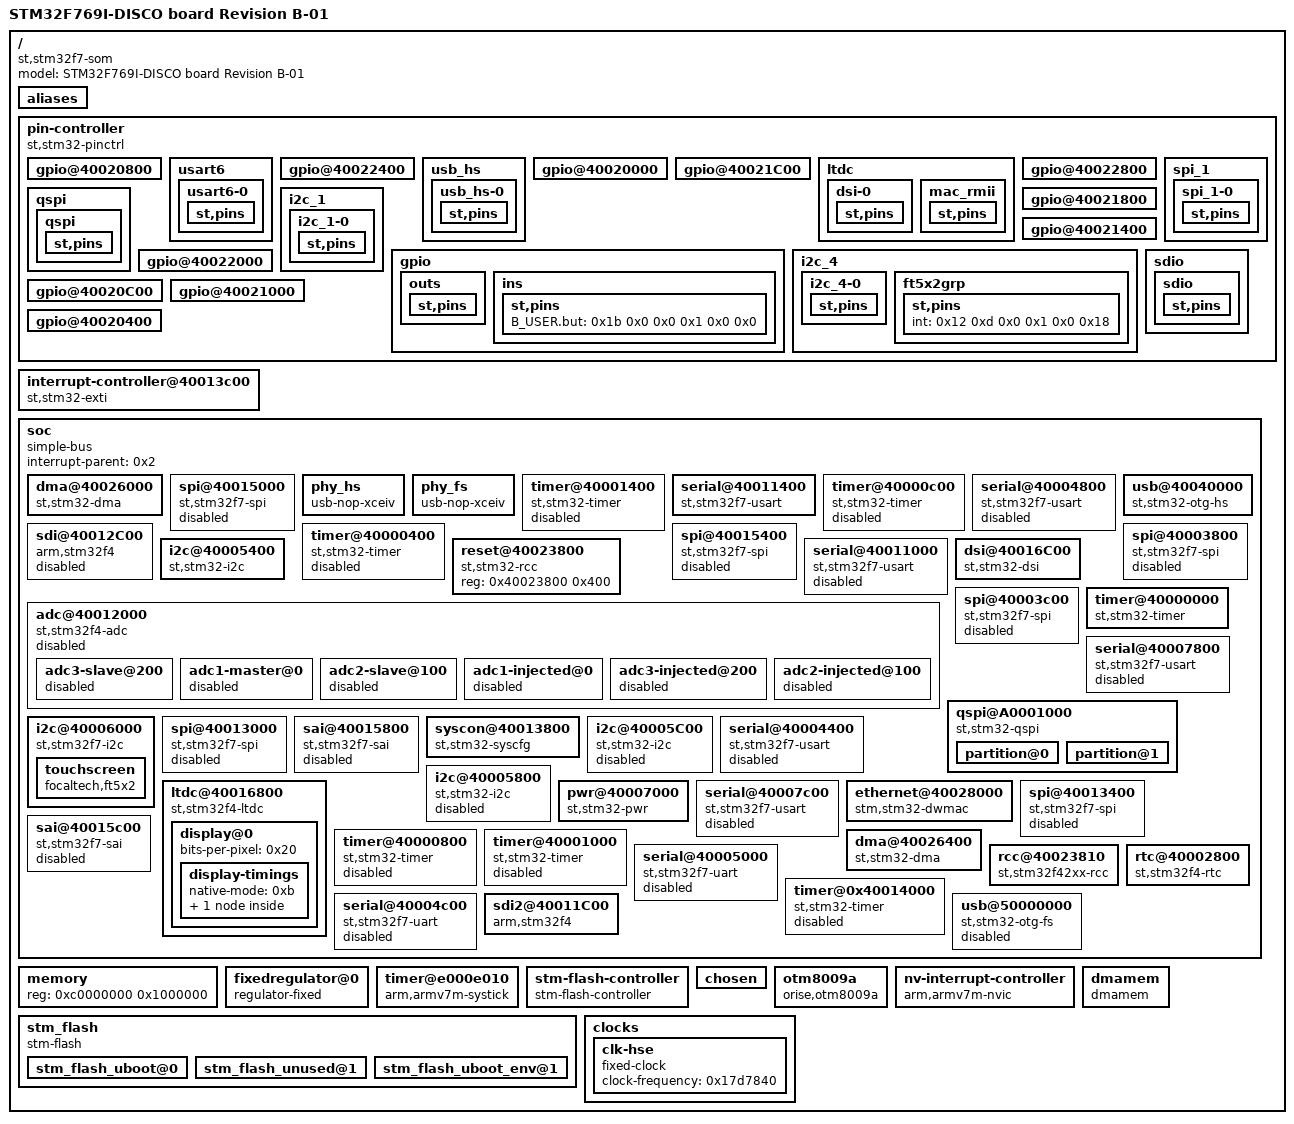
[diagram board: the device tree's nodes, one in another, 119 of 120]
/dts-v1/;

/ {
	model = "STM32F769I-DISCO board Revision B-01";
	#size-cells = <0x1>;
	#address-cells = <0x1>;
	compatible = "st,stm32f7-som", "st,stm32f7";

	aliases {
		spi3 = "/soc/spi@40013400";
		i2c2 = "/soc/i2c@40005C00";
		i2c1 = "/soc/i2c@40005800";
		gpio8 = "/pin-controller/gpio@40022000";
		ethernet0 = "/soc/ethernet@40028000";
		gpio2 = "/pin-controller/gpio@40020800";
		gpio0 = "/pin-controller/gpio@40020000";
		serial4 = "/soc/serial@40005000";
		serial7 = "/soc/serial@40007c00";
		spi5 = "/soc/spi@40015400";
		serial6 = "/soc/serial@40007800";
		serial3 = "/soc/serial@40004c00";
		gpio6 = "/pin-controller/gpio@40021800";
		i2c0 = "/soc/i2c@40005400";
		serial2 = "/soc/serial@40004800";
		serial0 = "/soc/serial@40011000";
		serial5 = "/soc/serial@40011400";
		gpio4 = "/pin-controller/gpio@40021000";
		gpio9 = "/pin-controller/gpio@40022400";
		spi1 = "/soc/spi@40003800";
		gpio10 = "/pin-controller/gpio@40022800";
		spi4 = "/soc/spi@40015000";
		gpio7 = "/pin-controller/gpio@40021C00";
		gpio1 = "/pin-controller/gpio@40020400";
		spi2 = "/soc/spi@40003c00";
		gpio5 = "/pin-controller/gpio@40021400";
		gpio3 = "/pin-controller/gpio@40020C00";
		spi0 = "/soc/spi@40013000";
		serial1 = "/soc/serial@40004400";
		i2c3 = "/soc/i2c@40006000";
	};

	pin-controller {
		#size-cells = <0x1>;
		ranges = <0x0 0x40020000 0x3000>;
		interrupt-parent = <0x3>;
		#address-cells = <0x1>;
		compatible = "st,stm32-pinctrl";
		st,syscfg = <0x19 0x8>;

		gpio@40020800 {
			resets = <0x4 0x82>;
			st,bank-name = "GPIOC";
			#gpio-cells = <0x2>;
			phandle = <0x1a>;
			gpio-controller;
			linux,phandle = <0x1a>;
			reg = <0x800 0x400>;
			clocks = <0x1 0x0 0x2>;
		};

		usart6 {

			usart6-0 {
				phandle = <0x8>;
				linux,phandle = <0x8>;

				st,pins {
					tx = <0x1a 0x6 0x22 0x0 0x0 0x0>;
					rx = <0x1a 0x7 0x22 0x0 0x0 0x0>;
				};
			};
		};

		gpio@40022400 {
			resets = <0x4 0x89>;
			st,bank-name = "GPIOJ";
			#gpio-cells = <0x2>;
			phandle = <0x13>;
			gpio-controller;
			linux,phandle = <0x13>;
			reg = <0x2400 0x400>;
			clocks = <0x1 0x0 0x9>;
		};

		usb_hs {

			usb_hs-0 {
				phandle = <0xe>;
				linux,phandle = <0xe>;

				st,pins {
					clk = <0x1b 0x5 0x2a 0x0 0x0 0x18>;
					data7 = <0x1e 0x5 0x2a 0x0 0x0 0x18>;
					dir = <0x12 0xb 0x2a 0x0 0x0 0x18>;
					data5 = <0x1e 0xc 0x2a 0x0 0x0 0x18>;
					data6 = <0x1e 0xd 0x2a 0x0 0x0 0x18>;
					data3 = <0x1e 0xa 0x2a 0x0 0x0 0x18>;
					nxt = <0x20 0x4 0x2a 0x0 0x0 0x18>;
					data2 = <0x1e 0x1 0x2a 0x0 0x0 0x18>;
					data1 = <0x1e 0x0 0x2a 0x0 0x0 0x18>;
					data4 = <0x1e 0xb 0x2a 0x0 0x0 0x18>;
					stp = <0x1a 0x0 0x2a 0x0 0x0 0x18>;
					data0 = <0x1b 0x3 0x2a 0x0 0x0 0x18>;
				};
			};
		};

		gpio@40020000 {
			resets = <0x4 0x80>;
			st,bank-name = "GPIOA";
			#gpio-cells = <0x2>;
			phandle = <0x1b>;
			gpio-controller;
			linux,phandle = <0x1b>;
			reg = <0x0 0x400>;
			clocks = <0x1 0x0 0x0>;
		};

		gpio@40021C00 {
			resets = <0x4 0x87>;
			st,bank-name = "GPIOH";
			#gpio-cells = <0x2>;
			phandle = <0x20>;
			gpio-controller;
			linux,phandle = <0x20>;
			reg = <0x1c00 0x400>;
			clocks = <0x1 0x0 0x7>;
		};

		ltdc {

			dsi-0 {
				phandle = <0x14>;
				linux,phandle = <0x14>;

				st,pins {
					bl = <0x12 0xe 0x1 0x1 0x0 0x0>;
					te = <0x13 0x2 0x36 0x0 0x0 0x18>;
				};
			};

			mac_rmii {
				phandle = <0xd>;
				linux,phandle = <0xd>;

				st,pins {
					txd1 = <0x1c 0xe 0x2e 0x0 0x0 0x18>;
					tx_en = <0x1c 0xb 0x2e 0x0 0x0 0x18>;
					mdio = <0x1b 0x2 0x2e 0x0 0x0 0x18>;
					crs_dv = <0x1b 0x7 0x2e 0x0 0x0 0x18>;
					ref_clk = <0x1b 0x1 0x2e 0x0 0x0 0x18>;
					mdc = <0x1a 0x1 0x2e 0x0 0x0 0x18>;
					rxd1 = <0x1a 0x5 0x2e 0x0 0x0 0x18>;
					txd0 = <0x1c 0xd 0x2e 0x0 0x0 0x18>;
					rxd0 = <0x1a 0x4 0x2e 0x0 0x0 0x18>;
					rx_er = <0x1d 0x5 0x2e 0x0 0x0 0x18>;
				};
			};
		};

		gpio@40022800 {
			resets = <0x4 0x8a>;
			st,bank-name = "GPIOK";
			#gpio-cells = <0x2>;
			gpio-controller;
			reg = <0x2800 0x400>;
			clocks = <0x1 0x0 0xa>;
		};

		spi_1 {

			spi_1-0 {

				st,pins {
					clk = <0x1e 0x2 0x26 0x1 0x0 0x10>;
					d3 = <0x1d 0xd 0x26 0x1 0x0 0x10>;
					d1 = <0x1a 0xa 0x26 0x1 0x0 0x10>;
					ncs = <0x1e 0x6 0x2a 0x1 0x0 0x10>;
					d2 = <0x1f 0x2 0x26 0x1 0x0 0x10>;
					d0 = <0x1a 0x9 0x26 0x1 0x0 0x10>;
				};
			};
		};

		qspi {

			qspi {
				phandle = <0x17>;
				linux,phandle = <0x17>;

				st,pins {
					clk = <0x1e 0x2 0x26 0x0 0x0 0x10>;
					d3 = <0x1d 0xd 0x26 0x0 0x0 0x10>;
					d1 = <0x1a 0xa 0x26 0x0 0x0 0x10>;
					ncs = <0x1e 0x6 0x2a 0x0 0x0 0x10>;
					d2 = <0x1f 0x2 0x26 0x0 0x0 0x10>;
					d0 = <0x1a 0x9 0x26 0x0 0x0 0x10>;
				};
			};
		};

		i2c_1 {

			i2c_1-0 {
				phandle = <0x6>;
				linux,phandle = <0x6>;

				st,pins {
					scl = <0x1e 0x8 0x12 0x1 0x4 0x0>;
					sda = <0x1e 0x9 0x12 0x1 0x4 0x0>;
				};
			};
		};

		gpio {

			outs {

				st,pins {
					ld_user1 = <0x13 0xd 0x1 0x1 0x0 0x0>;
					ld_user2 = <0x13 0x5 0x1 0x1 0x0 0x0>;
				};
			};

			ins {

				st,pins {
					B_USER.but = <0x1b 0x0 0x0 0x1 0x0 0x0>;
				};
			};
		};

		gpio@40021800 {
			resets = <0x4 0x86>;
			st,bank-name = "GPIOG";
			#gpio-cells = <0x2>;
			phandle = <0x1c>;
			gpio-controller;
			linux,phandle = <0x1c>;
			reg = <0x1800 0x400>;
			clocks = <0x1 0x0 0x6>;
		};

		gpio@40021400 {
			resets = <0x4 0x85>;
			st,bank-name = "GPIOF";
			#gpio-cells = <0x2>;
			gpio-controller;
			reg = <0x1400 0x400>;
			clocks = <0x1 0x0 0x5>;
		};

		i2c_4 {

			i2c_4-0 {
				phandle = <0x10>;
				linux,phandle = <0x10>;

				st,pins {
					scl = <0x1d 0xc 0x12 0x1 0x4 0x0>;
					sda = <0x1e 0x7 0x2e 0x1 0x4 0x0>;
				};
			};

			ft5x2grp {
				phandle = <0x11>;
				linux,phandle = <0x11>;

				st,pins {
					int = <0x12 0xd 0x0 0x1 0x0 0x18>;
				};
			};
		};

		gpio@40022000 {
			resets = <0x4 0x88>;
			st,bank-name = "GPIOI";
			#gpio-cells = <0x2>;
			phandle = <0x12>;
			gpio-controller;
			linux,phandle = <0x12>;
			reg = <0x2000 0x400>;
			clocks = <0x1 0x0 0x8>;
		};

		gpio@40020C00 {
			resets = <0x4 0x83>;
			st,bank-name = "GPIOD";
			#gpio-cells = <0x2>;
			phandle = <0x1d>;
			gpio-controller;
			linux,phandle = <0x1d>;
			reg = <0xc00 0x400>;
			clocks = <0x1 0x0 0x3>;
		};

		gpio@40021000 {
			resets = <0x4 0x84>;
			st,bank-name = "GPIOE";
			#gpio-cells = <0x2>;
			phandle = <0x1f>;
			gpio-controller;
			linux,phandle = <0x1f>;
			reg = <0x1000 0x400>;
			clocks = <0x1 0x0 0x4>;
		};

		sdio {

			sdio {
				phandle = <0x16>;
				linux,phandle = <0x16>;

				st,pins {
					cmd = <0x1d 0x7 0x2e 0x0 0x0 0x10>;
					d3 = <0x1e 0x4 0x2a 0x0 0x0 0x10>;
					ck = <0x1d 0x6 0x2e 0x0 0x0 0x10>;
					d1 = <0x1c 0xa 0x2e 0x0 0x0 0x10>;
					d2 = <0x1e 0x3 0x2a 0x0 0x0 0x10>;
					cd = <0x12 0xf 0x0 0x1 0x0 0x10>;
					d0 = <0x1c 0x9 0x2e 0x0 0x0 0x10>;
				};
			};
		};

		gpio@40020400 {
			resets = <0x4 0x81>;
			st,bank-name = "GPIOB";
			#gpio-cells = <0x2>;
			phandle = <0x1e>;
			gpio-controller;
			linux,phandle = <0x1e>;
			reg = <0x400 0x400>;
			clocks = <0x1 0x0 0x1>;
		};
	};

	interrupt-controller@40013c00 {
		interrupt-controller;
		interrupt-parent = <0x2>;
		phandle = <0x3>;
		compatible = "st,stm32-exti", "syscon";
		linux,phandle = <0x3>;
		interrupts = <0x1 0x2 0x3 0x6 0x7 0x8 0x9 0xa 0x17 0x28 0x29 0x2a 0x3e 0x4c>;
		#interrupt-cells = <0x2>;
		reg = <0x40013c00 0x400>;
	};

	soc {
		#size-cells = <0x1>;
		ranges;
		interrupt-parent = <0x2>;
		#address-cells = <0x1>;
		compatible = "simple-bus";

		dma@40026000 {
			#dma-cells = <0x4>;
			phandle = <0x5>;
			compatible = "st,stm32-dma";
			linux,phandle = <0x5>;
			status = "okay";
			interrupts = <0xb 0xc 0xd 0xe 0xf 0x10 0x11 0x2f>;
			reg = <0x40026000 0x400>;
			st,streams = <0x8>;
			clocks = <0x1 0x0 0x15>;
		};

		spi@40015000 {
			resets = <0x4 0x134>;
			#size-cells = <0x0>;
			#address-cells = <0x1>;
			compatible = "st,stm32f7-spi";
			status = "disabled";
			interrupts = <0x55>;
			reg = <0x40015000 0x400>;
			clocks = <0x1 0x0 0xb4>;
		};

		phy_hs {
			#phy-cells = <0x0>;
			phandle = <0xf>;
			compatible = "usb-nop-xceiv";
			linux,phandle = <0xf>;
		};

		phy_fs {
			#phy-cells = <0x0>;
			compatible = "usb-nop-xceiv";
		};

		timer@40001400 {
			compatible = "st,stm32-timer";
			status = "disabled";
			interrupts = <0x37>;
			reg = <0x40001400 0x400>;
			clocks = <0x1 0x0 0x85>;
		};

		serial@40011400 {
			st,use-dma-rx;
			pinctrl-0 = <0x8>;
			dmas = <0x7 0x2 0x5 0x400 0x0 0x7 0x6 0x5 0x400 0x0>;
			compatible = "st,stm32f7-usart", "st,stm32f7-uart";
			st,use-dma-tx;
			status = "okay";
			dma-names = "rx", "tx";
			interrupts = <0x47>;
			reg = <0x40011400 0x400>;
			pinctrl-names = "default";
			clocks = <0x1 0x0 0xa5>;
		};

		timer@40000c00 {
			compatible = "st,stm32-timer";
			status = "disabled";
			interrupts = <0x32>;
			reg = <0x40000c00 0x400>;
			clocks = <0x1 0x0 0x83>;
		};

		serial@40004800 {
			dmas = <0x5 0x1 0x4 0x400 0x0 0x5 0x3 0x4 0x400 0x0>;
			compatible = "st,stm32f7-usart", "st,stm32f7-uart";
			status = "disabled";
			dma-names = "rx", "tx";
			interrupts = <0x27>;
			reg = <0x40004800 0x400>;
			clocks = <0x1 0x0 0x92>;
		};

		usb@40040000 {
			g-tx-fifo-size = <0x34 0x17a>;
			usb2-phy = <0xf>;
			g-gpio = <0x210000>;
			pinctrl-0 = <0xe>;
			compatible = "st,stm32-otg-hs";
			g-rx-fifo-size = <0x200>;
			dr_mode = "host";
			status = "okay";
			interrupts = <0x4d>;
			reg = <0x40040000 0x40000>;
			g-np-tx-fifo-size = <0x40>;
			pinctrl-names = "default";
			clocks = <0x1 0x0 0x1d 0x1 0x0 0x1e>;
			clock-names = "core_clk", "ulpi_clk";
		};

		timer@40000400 {
			compatible = "st,stm32-timer";
			status = "disabled";
			interrupts = <0x1d>;
			reg = <0x40000400 0x400>;
			clocks = <0x1 0x0 0x81>;
		};

		sdi@40012C00 {
			max-frequency = <0x17d7840>;
			voltage-ranges = <0xc80 0xce4 0xce4 0xd48>;
			vmmc-supply = <0x9>;
			dmas = <0x7 0x3 0x4 0x400 0x3 0x7 0x3 0x4 0x400 0x3>;
			arm,primecell-periphid = <0x40480180>;
			compatible = "arm,stm32f4", "arm,primecell";
			status = "disabled";
			dma-names = "rx", "tx";
			interrupts = <0x31>;
			bus-width = <0x4>;
			reg = <0x40012c00 0x400>;
			clocks = <0x1 0x0 0xab>;
			clock-names = "apb_pclk";
		};

		spi@40015400 {
			resets = <0x4 0x135>;
			#size-cells = <0x0>;
			#address-cells = <0x1>;
			compatible = "st,stm32f7-spi";
			status = "disabled";
			interrupts = <0x56>;
			reg = <0x40015400 0x400>;
			clocks = <0x1 0x0 0xb5>;
		};

		spi@40003800 {
			resets = <0x4 0x10e>;
			#size-cells = <0x0>;
			#address-cells = <0x1>;
			compatible = "st,stm32f7-spi";
			status = "disabled";
			interrupts = <0x24>;
			reg = <0x40003800 0x400>;
			clocks = <0x1 0x0 0x8e>;
		};

		i2c@40005400 {
			resets = <0x4 0x115>;
			pinctrl-0 = <0x6>;
			dmas = <0x5 0x0 0x1 0x400 0x0 0x5 0x6 0x1 0x400 0x0>;
			compatible = "st,stm32-i2c", "st,stm32f7-i2c";
			timingr = <0x60201e2b>;
			status = "okay";
			dma-names = "rx", "tx";
			interrupts = <0x1f 0x20>;
			reg = <0x40005400 0x400>;
			pinctrl-names = "default";
			clocks = <0x1 0x0 0x95>;
		};

		reset@40023800 {
			#reset-cells = <0x1>;
			phandle = <0x4>;
			compatible = "st,stm32-rcc";
			linux,phandle = <0x4>;
			reg = <0x40023800 0x400>;
		};

		serial@40011000 {
			dmas = <0x7 0x5 0x4 0x400 0x0 0x7 0x7 0x4 0x400 0x0>;
			compatible = "st,stm32f7-usart", "st,stm32f7-uart";
			status = "disabled";
			dma-names = "rx", "tx";
			interrupts = <0x25>;
			reg = <0x40011000 0x400>;
			clocks = <0x1 0x0 0xa4>;
		};

		adc@40012000 {
			#size-cells = <0x0>;
			#address-cells = <0x1>;
			compatible = "st,stm32f4-adc";
			status = "disabled";
			interrupts = <0x12>;
			reg = <0x40012000 0x400>;
			clocks = <0x1 0x0 0xa8>;
			clock-names = "adc";

			adc3-slave@200 {
				#io-channel-cells = <0x1>;
				status = "disabled";
				reg = <0x200>;
				clocks = <0x1 0x0 0xaa>;
			};

			adc1-master@0 {
				#io-channel-cells = <0x1>;
				dmas = <0x7 0x4 0x0 0x400 0x0>;
				status = "disabled";
				dma-names = "rx";
				reg = <0x0>;
				clocks = <0x1 0x0 0xa8>;
			};

			adc2-slave@100 {
				#io-channel-cells = <0x1>;
				status = "disabled";
				reg = <0x100>;
				clocks = <0x1 0x0 0xa9>;
			};

			adc1-injected@0 {
				st,injected;
				#io-channel-cells = <0x1>;
				status = "disabled";
				reg = <0x0>;
				clocks = <0x1 0x0 0xa8>;
			};

			adc3-injected@200 {
				st,injected;
				#io-channel-cells = <0x1>;
				status = "disabled";
				reg = <0x200>;
				clocks = <0x1 0x0 0xaa>;
			};

			adc2-injected@100 {
				st,injected;
				#io-channel-cells = <0x1>;
				status = "disabled";
				reg = <0x100>;
				clocks = <0x1 0x0 0xa9>;
			};
		};

		dsi@40016C00 {
			resets = <0x4 0x13b>;
			panel = <0x15>;
			te = <0x1>;
			pinctrl-0 = <0x14>;
			compatible = "st,stm32-dsi";
			lanes = <0x2>;
			status = "okay";
			interrupts = <0x62>;
			backlight-gpios = <0x12 0xe 0x0>;
			reg = <0x40016c00 0x800>;
			pinctrl-names = "default";
			clocks = <0x1 0x0 0xbb>;
		};

		spi@40003c00 {
			resets = <0x4 0x10f>;
			#size-cells = <0x0>;
			#address-cells = <0x1>;
			compatible = "st,stm32f7-spi";
			status = "disabled";
			interrupts = <0x33>;
			reg = <0x40003c00 0x400>;
			clocks = <0x1 0x0 0x8f>;
		};

		timer@40000000 {
			compatible = "st,stm32-timer";
			status = "okay";
			interrupts = <0x1c>;
			reg = <0x40000000 0x400>;
			clocks = <0x1 0x0 0x80>;
		};

		serial@40007800 {
			dmas = <0x5 0x3 0x5 0x400 0x0 0x5 0x1 0x5 0x400 0x0>;
			compatible = "st,stm32f7-usart", "st,stm32f7-uart";
			status = "disabled";
			dma-names = "rx", "tx";
			interrupts = <0x52>;
			reg = <0x40007800 0x400>;
			clocks = <0x1 0x0 0x9e>;
		};

		qspi@A0001000 {
			resets = <0x4 0xc1>;
			#size-cells = <0x1>;
			pinctrl-0 = <0x17>;
			#address-cells = <0x1>;
			dmas = <0x7 0x7 0x3 0x400 0x0>;
			flash = "mt25ql512abb";
			freq = <0x66ff300>;
			compatible = "st,stm32-qspi";
			status = "okay";
			dma-names = "tx";
			interrupts = <0x5c>;
			reg = <0xa0001000 0x1000 0x90000000 0x10000000>;
			pinctrl-names = "default";
			clocks = <0x1 0x0 0x41>;

			partition@0 {
				label = "stm_qspi_linux_image";
				reg = <0x0 0xa00000>;
			};

			partition@1 {
				label = "stm_qspi_fs";
				reg = <0xa00000 0x3600000>;
			};
		};

		i2c@40006000 {
			resets = <0x4 0x118>;
			#size-cells = <0x0>;
			pinctrl-0 = <0x10>;
			#address-cells = <0x1>;
			dmas = <0x5 0x2 0x2 0x400 0x0 0x5 0x5 0x2 0x400 0x0>;
			compatible = "st,stm32f7-i2c";
			timingr = <0x60201e2b>;
			status = "okay";
			dma-names = "rx", "tx";
			interrupts = <0x5f 0x60>;
			reg = <0x40006000 0x400>;
			pinctrl-names = "default";
			clocks = <0x1 0x0 0x98>;

			touchscreen {
				irq-gpios = <0x12 0xd 0x1>;
				pinctrl-0 = <0x11>;
				compatible = "focaltech,ft5x2";
				reset-gpios = <0x13 0xf 0x1>;
				reg = <0x2a>;
				pinctrl-names = "default";
				x-max = <0x320>;
				y-max = <0x1e0>;
			};
		};

		spi@40013000 {
			resets = <0x4 0x12c>;
			#size-cells = <0x0>;
			#address-cells = <0x1>;
			dmas = <0x7 0x0 0x3 0x400 0x0 0x7 0x3 0x3 0x400 0x0>;
			compatible = "st,stm32f7-spi";
			status = "disabled";
			dma-names = "rx", "tx";
			interrupts = <0x23>;
			reg = <0x40013000 0x400>;
			clocks = <0x1 0x0 0xac>;
		};

		sai@40015800 {
			resets = <0x4 0x136>;
			compatible = "st,stm32f7-sai";
			status = "disabled";
			interrupts = <0x57>;
			reg = <0x40015800 0x400>;
			clocks = <0x1 0x0 0xb6>;
		};

		syscon@40013800 {
			phandle = <0x19>;
			compatible = "st,stm32-syscfg", "syscon";
			linux,phandle = <0x19>;
			reg = <0x40013800 0x24>;
			clocks = <0x1 0x0 0xae>;
			clock-names = "core_clk";
		};

		i2c@40005C00 {
			resets = <0x4 0x117>;
			compatible = "st,stm32-i2c";
			status = "disabled";
			interrupts = <0x48 0x49>;
			reg = <0x40005c00 0x400>;
			clocks = <0x1 0x0 0x97>;
		};

		serial@40004400 {
			compatible = "st,stm32f7-usart", "st,stm32f7-uart";
			status = "disabled";
			interrupts = <0x26>;
			reg = <0x40004400 0x400>;
			clocks = <0x1 0x0 0x91>;
		};

		ltdc@40016800 {
			display = <0xa>;
			compatible = "st,stm32f4-ltdc";
			status = "okay";
			reg = <0x40016800 0x400>;
			clocks = <0x1 0x0 0xba 0x1 0x0 0xb6>;
			clock-names = "ltdc", "sai1";

			display@0 {
				phandle = <0xa>;
				linux,phandle = <0xa>;
				bits-per-pixel = <0x20>;

				display-timings {
					native-mode = <0xb>;

					mb1166 {
						vsync-active = <0x1>;
						clock-frequency = <0x1a11188>;
						hfront-porch = <0x78>;
						pixelclk-active = <0x0>;
						phandle = <0xb>;
						hactive = <0x320>;
						vfront-porch = <0xc>;
						vsync-len = <0x3f>;
						hsync-active = <0x1>;
						linux,phandle = <0xb>;
						vback-porch = <0xc>;
						vactive = <0x1e0>;
						hback-porch = <0x78>;
						hsync-len = <0xc>;
					};
				};
			};
		};

		i2c@40005800 {
			resets = <0x4 0x116>;
			compatible = "st,stm32-i2c";
			status = "disabled";
			interrupts = <0x21 0x22>;
			reg = <0x40005800 0x400>;
			clocks = <0x1 0x0 0x96>;
		};

		pwr@40007000 {
			compatible = "st,stm32-pwr", "syscon";
			reg = <0x40007000 0x400>;
			clocks = <0x1 0x0 0x9c>;
		};

		serial@40007c00 {
			compatible = "st,stm32f7-usart", "st,stm32f7-uart";
			status = "disabled";
			interrupts = <0x53>;
			reg = <0x40007c00 0x400>;
			clocks = <0x1 0x0 0x9f>;
		};

		ethernet@40028000 {
			mac-address = [c0 b1 3c 88 88 85];
			local-mac-address = [c0 b1 3c 88 88 85];
			resets = <0x4 0x99>;
			interrupt-names = "macirq";
			pinctrl-0 = <0xd>;
			compatible = "stm,stm32-dwmac", "snps,dwmac-3.611", "snps,dwmac";
			status = "okay";
			interrupts = <0x3d>;
			reg = <0x40028000 0x2000>;
			pinctrl-names = "default";
			reset-names = "stmmaceth";
			clocks = <0x1 0x0 0x19 0x1 0x0 0x1a 0x1 0x0 0x1b>;
			clock-names = "stmmaceth", "stm32_mac_tx", "stm32_mac_rx";
			phy-mode = "rmii";
		};

		spi@40013400 {
			resets = <0x4 0x12d>;
			#size-cells = <0x0>;
			#address-cells = <0x1>;
			compatible = "st,stm32f7-spi";
			status = "disabled";
			interrupts = <0x54>;
			reg = <0x40013400 0x400>;
			clocks = <0x1 0x0 0xad>;
		};

		timer@40000800 {
			compatible = "st,stm32-timer";
			status = "disabled";
			interrupts = <0x1e>;
			reg = <0x40000800 0x400>;
			clocks = <0x1 0x0 0x82>;
		};

		timer@40001000 {
			compatible = "st,stm32-timer";
			status = "disabled";
			interrupts = <0x36>;
			reg = <0x40001000 0x400>;
			clocks = <0x1 0x0 0x84>;
		};

		dma@40026400 {
			#dma-cells = <0x4>;
			phandle = <0x7>;
			compatible = "st,stm32-dma";
			linux,phandle = <0x7>;
			status = "okay";
			interrupts = <0x38 0x39 0x3a 0x3b 0x3c 0x44 0x45 0x46>;
			reg = <0x40026400 0x400>;
			st,streams = <0x8>;
			clocks = <0x1 0x0 0x16>;
		};

		serial@40005000 {
			compatible = "st,stm32f7-uart";
			status = "disabled";
			interrupts = <0x35>;
			reg = <0x40005000 0x400>;
			clocks = <0x1 0x0 0x94>;
		};

		rcc@40023810 {
			phandle = <0x1>;
			compatible = "st,stm32f42xx-rcc", "syscon";
			linux,phandle = <0x1>;
			#clock-cells = <0x2>;
			reg = <0x40023800 0x400>;
			clocks = <0xc>;
		};

		sai@40015c00 {
			resets = <0x4 0x137>;
			dmas = <0x7 0x4 0x3 0x400 0x0>;
			compatible = "st,stm32f7-sai";
			status = "disabled";
			dma-names = "tx";
			interrupts = <0x5b>;
			reg = <0x40015c00 0x400>;
			clocks = <0x1 0x0 0xb7>;
		};

		rtc@40002800 {
			interrupt-parent = <0x3>;
			exti-line-wakeup = <0x16>;
			exti-line-alarm = <0x11>;
			compatible = "st,stm32f4-rtc";
			status = "okay";
			reg = <0x40002800 0x400>;
		};

		timer@0x40014000 {
			compatible = "st,stm32-timer";
			status = "disabled";
			interrupts = <0x18>;
			reg = <0x40014000 0x400>;
			clocks = <0x1 0x0 0xb0>;
		};

		serial@40004c00 {
			compatible = "st,stm32f7-uart";
			status = "disabled";
			interrupts = <0x34>;
			reg = <0x40004c00 0x400>;
			clocks = <0x1 0x0 0x93>;
		};

		sdi2@40011C00 {
			max-frequency = <0x17d7840>;
			resets = <0x4 0x127>;
			voltage-ranges = <0xc80 0xce4 0xce4 0xd48>;
			vmmc-supply = <0x9>;
			pinctrl-0 = <0x16>;
			dmas = <0x7 0x0 0xb 0x400 0x0 0x7 0x0 0xb 0x400 0x0>;
			arm,primecell-periphid = <0x40480180>;
			compatible = "arm,stm32f4", "arm,primecell";
			status = "okay";
			dma-names = "rx", "tx";
			interrupts = <0x67>;
			bus-width = <0x4>;
			reg = <0x40011c00 0x400>;
			pinctrl-names = "default";
			cd-gpio = <0x12 0xf 0x1>;
			clocks = <0x1 0x0 0xa7>;
			clock-names = "apb_pclk";
		};

		usb@50000000 {
			compatible = "st,stm32-otg-fs";
			status = "disabled";
			interrupts = <0x43>;
			reg = <0x50000000 0x40000>;
			clocks = <0x1 0x0 0x27>;
			clock-names = "core_clk";
		};
	};

	memory {
		reg = <0xc0000000 0x1000000>;
		device_type = "memory";
	};

	fixedregulator@0 {
		phandle = <0x9>;
		regulator-min-microvolt = <0x325aa0>;
		regulator-boot-on;
		compatible = "regulator-fixed";
		linux,phandle = <0x9>;
		regulator-name = "vmmc";
		regulator-max-microvolt = <0x325aa0>;
	};

	timer@e000e010 {
		compatible = "arm,armv7m-systick";
		status = "okay";
		reg = <0xe000e010 0x10>;
		clocks = <0x1 0x1 0x0>;
	};

	stm-flash-controller {
		interrupt-parent = <0x2>;
		phandle = <0x18>;
		compatible = "stm-flash-controller";
		linux,phandle = <0x18>;
		interrupts = <0x4>;
		reg = <0x40023c00 0x400>;
	};

	chosen {
		bootargs = "stm32_platform=stm32f7-disco console=ttyS5,115200 panic=3";
		linux,stdout-path = "/soc/serial@40011400";
	};

	otm8009a {
		phandle = <0x15>;
		compatible = "orise,otm8009a";
		linux,phandle = <0x15>;
	};

	nv-interrupt-controller {
		interrupt-controller;
		phandle = <0x2>;
		compatible = "arm,armv7m-nvic";
		linux,phandle = <0x2>;
		#interrupt-cells = <0x1>;
		reg = <0xe000e100 0xc00>;
	};

	stm_flash {
		#size-cells = <0x1>;
		geometry = "stm32f76x.2M";
		#address-cells = <0x1>;
		flash-controller = <0x18>;
		linux,mtd-name = "physmap-stm-flash.0";
		compatible = "stm-flash";
		probe-type = "stm_probe";
		status = "okay";
		reg = <0x8000000 0x200000>;
		bank-width = <0x2>;

		stm_flash_uboot@0 {
			label = "stm_flash_uboot";
			reg = <0x0 0x20000>;
		};

		stm_flash_unused@1 {
			label = "stm_flash_unused";
			reg = <0x40000 0x1c0000>;
		};

		stm_flash_uboot_env@1 {
			label = "stm_flash_uboot_env";
			reg = <0x20000 0x20000>;
		};
	};

	dmamem {
		full-size = <0x200000>;
		fb-size = <0x177000>;
		base-addr = <0xc0600000>;
		compatible = "dmamem";
	};

	clocks {

		clk-hse {
			clock-frequency = <0x17d7840>;
			phandle = <0xc>;
			compatible = "fixed-clock";
			linux,phandle = <0xc>;
			#clock-cells = <0x0>;
		};
	};
};
